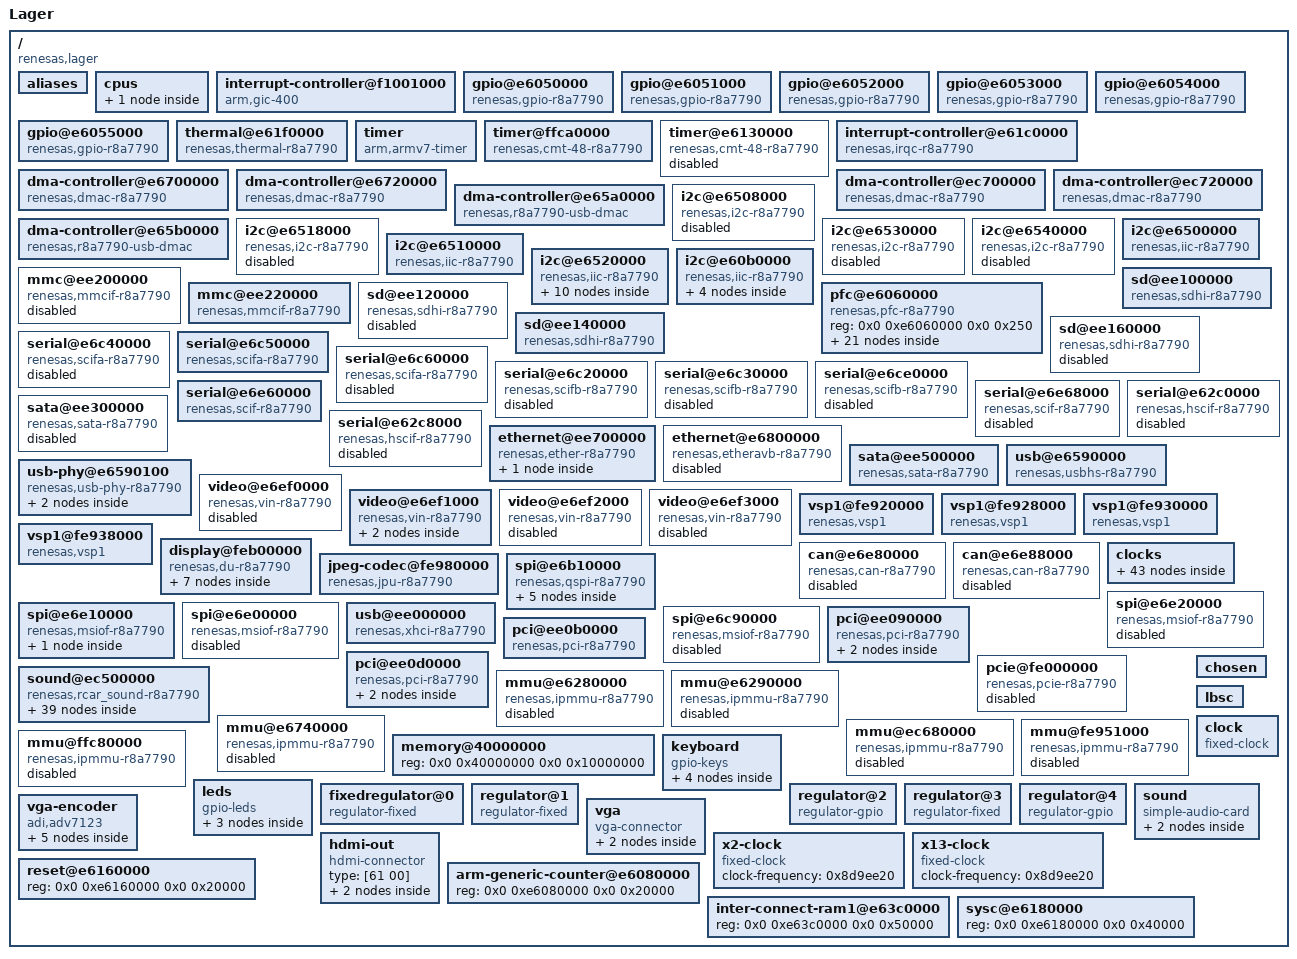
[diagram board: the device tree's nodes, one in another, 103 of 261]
/dts-v1/;

/ {
	compatible = "renesas,lager", "renesas,r8a7790";
	interrupt-parent = <0x1>;
	#address-cells = <0x2>;
	#size-cells = <0x2>;
	model = "Lager";

	aliases {
		i2c0 = "/i2c@e6508000";
		i2c1 = "/i2c@e6518000";
		i2c2 = "/i2c@e6530000";
		i2c3 = "/i2c@e6540000";
		i2c4 = "/i2c@e6500000";
		i2c5 = "/i2c@e6510000";
		i2c6 = "/i2c@e6520000";
		i2c7 = "/i2c@e60b0000";
		spi0 = "/spi@e6b10000";
		spi1 = "/spi@e6e20000";
		spi2 = "/spi@e6e10000";
		spi3 = "/spi@e6e00000";
		spi4 = "/spi@e6c90000";
		vin0 = "/video@e6ef0000";
		vin1 = "/video@e6ef1000";
		vin2 = "/video@e6ef2000";
		vin3 = "/video@e6ef3000";
		serial6 = "/serial@e6e60000";
		serial7 = "/serial@e6e68000";
	};

	cpus {
		#address-cells = <0x1>;
		#size-cells = <0x0>;

		cpu@0 {
			device_type = "cpu";
			compatible = "arm,gic-400";
			reg = <0x0>;
			clock-frequency = "M|m";
			voltage-tolerance = <0x1>;
			clocks = <0x2 0x9>;
			clock-latency = <0x493e0>;
			operating-points = <0x155cc0 0xf4240 0x12b128 0xf4240 0x100590 0xf4240 0xd59f8 0xf4240 0xaae60 0xf4240 0x55730 0xf4240>;
			cpu0-supply = <0x3>;
		};
	};

	interrupt-controller@f1001000 {
		compatible = "arm,gic-400";
		#interrupt-cells = <0x3>;
		#address-cells = <0x0>;
		interrupt-controller;
		reg = <0x0 0xf1001000 0x0 0x1000 0x0 0xf1002000 0x0 0x1000 0x0 0xf1004000 0x0 0x2000 0x0 0xf1006000 0x0 0x2000>;
		interrupts = <0x1 0x9 0xf04>;
		linux,phandle = <0x1>;
		phandle = <0x1>;
	};

	gpio@e6050000 {
		compatible = "renesas,gpio-r8a7790", "renesas,gpio-rcar";
		reg = <0x0 0xe6050000 0x0 0x50>;
		interrupts = <0x0 0x4 0x4>;
		#gpio-cells = <0x2>;
		gpio-controller;
		gpio-ranges = <0x4 0x0 0x0 0x20>;
		#interrupt-cells = <0x2>;
		interrupt-controller;
		clocks = <0x5 0xc>;
		power-domains = <0x2>;
	};

	gpio@e6051000 {
		compatible = "renesas,gpio-r8a7790", "renesas,gpio-rcar";
		reg = <0x0 0xe6051000 0x0 0x50>;
		interrupts = <0x0 0x5 0x4>;
		#gpio-cells = <0x2>;
		gpio-controller;
		gpio-ranges = <0x4 0x0 0x20 0x1e>;
		#interrupt-cells = <0x2>;
		interrupt-controller;
		clocks = <0x5 0xb>;
		power-domains = <0x2>;
		linux,phandle = <0x11>;
		phandle = <0x11>;
	};

	gpio@e6052000 {
		compatible = "renesas,gpio-r8a7790", "renesas,gpio-rcar";
		reg = <0x0 0xe6052000 0x0 0x50>;
		interrupts = <0x0 0x6 0x4>;
		#gpio-cells = <0x2>;
		gpio-controller;
		gpio-ranges = <0x4 0x0 0x40 0x1e>;
		#interrupt-cells = <0x2>;
		interrupt-controller;
		clocks = <0x5 0xa>;
		power-domains = <0x2>;
	};

	gpio@e6053000 {
		compatible = "renesas,gpio-r8a7790", "renesas,gpio-rcar";
		reg = <0x0 0xe6053000 0x0 0x50>;
		interrupts = <0x0 0x7 0x4>;
		#gpio-cells = <0x2>;
		gpio-controller;
		gpio-ranges = <0x4 0x0 0x60 0x20>;
		#interrupt-cells = <0x2>;
		interrupt-controller;
		clocks = <0x5 0x9>;
		power-domains = <0x2>;
		linux,phandle = <0x1c>;
		phandle = <0x1c>;
	};

	gpio@e6054000 {
		compatible = "renesas,gpio-r8a7790", "renesas,gpio-rcar";
		reg = <0x0 0xe6054000 0x0 0x50>;
		interrupts = <0x0 0x8 0x4>;
		#gpio-cells = <0x2>;
		gpio-controller;
		gpio-ranges = <0x4 0x0 0x80 0x20>;
		#interrupt-cells = <0x2>;
		interrupt-controller;
		clocks = <0x5 0x8>;
		power-domains = <0x2>;
		linux,phandle = <0x5a>;
		phandle = <0x5a>;
	};

	gpio@e6055000 {
		compatible = "renesas,gpio-r8a7790", "renesas,gpio-rcar";
		reg = <0x0 0xe6055000 0x0 0x50>;
		interrupts = <0x0 0x9 0x4>;
		#gpio-cells = <0x2>;
		gpio-controller;
		gpio-ranges = <0x4 0x0 0xa0 0x20>;
		#interrupt-cells = <0x2>;
		interrupt-controller;
		clocks = <0x5 0x7>;
		power-domains = <0x2>;
		linux,phandle = <0x2b>;
		phandle = <0x2b>;
	};

	thermal@e61f0000 {
		compatible = "renesas,thermal-r8a7790", "renesas,rcar-thermal";
		reg = <0x0 0xe61f0000 0x0 0x14 0x0 0xe61f0100 0x0 0x38>;
		interrupts = <0x0 0x45 0x4>;
		clocks = <0x6 0x16>;
		power-domains = <0x2>;
	};

	timer {
		compatible = "arm,armv7-timer";
		interrupts = <0x1 0xd 0xf08 0x1 0xe 0xf08 0x1 0xb 0xf08 0x1 0xa 0xf08>;
	};

	timer@ffca0000 {
		compatible = "renesas,cmt-48-r8a7790", "renesas,cmt-48-gen2";
		reg = <0x0 0xffca0000 0x0 0x1004>;
		interrupts = <0x0 0x8e 0x4 0x0 0x8f 0x4>;
		clocks = <0x7 0x18>;
		clock-names = "fck";
		power-domains = <0x2>;
		renesas,channels-mask = <0x60>;
		status = "okay";
	};

	timer@e6130000 {
		compatible = "renesas,cmt-48-r8a7790", "renesas,cmt-48-gen2";
		reg = <0x0 0xe6130000 0x0 0x1004>;
		interrupts = <0x0 0x78 0x4 0x0 0x79 0x4 0x0 0x7a 0x4 0x0 0x7b 0x4 0x0 0x7c 0x4 0x0 0x7d 0x4 0x0 0x7e 0x4 0x0 0x7f 0x4>;
		clocks = <0x8 0x1d>;
		clock-names = "fck";
		power-domains = <0x2>;
		renesas,channels-mask = <0xff>;
		status = "disabled";
	};

	interrupt-controller@e61c0000 {
		compatible = "renesas,irqc-r8a7790", "renesas,irqc";
		#interrupt-cells = <0x2>;
		interrupt-controller;
		reg = <0x0 0xe61c0000 0x0 0x200>;
		interrupts = <0x0 0x0 0x4 0x0 0x1 0x4 0x0 0x2 0x4 0x0 0x3 0x4>;
		clocks = <0x9 0x7>;
		power-domains = <0x2>;
		linux,phandle = <0x15>;
		phandle = <0x15>;
	};

	dma-controller@e6700000 {
		compatible = "renesas,dmac-r8a7790", "renesas,rcar-dmac";
		reg = <0x0 0xe6700000 0x0 0x20000>;
		interrupts = <0x0 0xc5 0x4 0x0 0xc8 0x4 0x0 0xc9 0x4 0x0 0xca 0x4 0x0 0xcb 0x4 0x0 0xcc 0x4 0x0 0xcd 0x4 0x0 0xce 0x4 0x0 0xcf 0x4 0x0 0xd0 0x4 0x0 0xd1 0x4 0x0 0xd2 0x4 0x0 0xd3 0x4 0x0 0xd4 0x4 0x0 0xd5 0x4 0x0 0xd6 0x4>;
		interrupt-names = "error", "ch0", "ch1", "ch2", "ch3", "ch4", "ch5", "ch6", "ch7", "ch8", "ch9", "ch10", "ch11", "ch12", "ch13", "ch14";
		clocks = <0xa 0x13>;
		clock-names = "fck";
		power-domains = <0x2>;
		#dma-cells = <0x1>;
		dma-channels = <0xf>;
		linux,phandle = <0xb>;
		phandle = <0xb>;
	};

	dma-controller@e6720000 {
		compatible = "renesas,dmac-r8a7790", "renesas,rcar-dmac";
		reg = <0x0 0xe6720000 0x0 0x20000>;
		interrupts = <0x0 0xdc 0x4 0x0 0xd8 0x4 0x0 0xd9 0x4 0x0 0xda 0x4 0x0 0xdb 0x4 0x0 0x134 0x4 0x0 0x135 0x4 0x0 0x136 0x4 0x0 0x137 0x4 0x0 0x138 0x4 0x0 0x139 0x4 0x0 0x13a 0x4 0x0 0x13b 0x4 0x0 0x13c 0x4 0x0 0x13d 0x4 0x0 0x13e 0x4>;
		interrupt-names = "error", "ch0", "ch1", "ch2", "ch3", "ch4", "ch5", "ch6", "ch7", "ch8", "ch9", "ch10", "ch11", "ch12", "ch13", "ch14";
		clocks = <0xa 0x12>;
		clock-names = "fck";
		power-domains = <0x2>;
		#dma-cells = <0x1>;
		dma-channels = <0xf>;
		linux,phandle = <0x18>;
		phandle = <0x18>;
	};

	dma-controller@ec700000 {
		compatible = "renesas,dmac-r8a7790", "renesas,rcar-dmac";
		reg = <0x0 0xec700000 0x0 0x10000>;
		interrupts = <0x0 0x15a 0x4 0x0 0x140 0x4 0x0 0x141 0x4 0x0 0x142 0x4 0x0 0x143 0x4 0x0 0x144 0x4 0x0 0x145 0x4 0x0 0x146 0x4 0x0 0x147 0x4 0x0 0x148 0x4 0x0 0x149 0x4 0x0 0x14a 0x4 0x0 0x14b 0x4 0x0 0x14c 0x4>;
		interrupt-names = "error", "ch0", "ch1", "ch2", "ch3", "ch4", "ch5", "ch6", "ch7", "ch8", "ch9", "ch10", "ch11", "ch12";
		clocks = <0x6 0x2>;
		clock-names = "fck";
		power-domains = <0x2>;
		#dma-cells = <0x1>;
		dma-channels = <0xd>;
		linux,phandle = <0x52>;
		phandle = <0x52>;
	};

	dma-controller@ec720000 {
		compatible = "renesas,dmac-r8a7790", "renesas,rcar-dmac";
		reg = <0x0 0xec720000 0x0 0x10000>;
		interrupts = <0x0 0x15b 0x4 0x0 0x14d 0x4 0x0 0x14e 0x4 0x0 0x14f 0x4 0x0 0x150 0x4 0x0 0x151 0x4 0x0 0x152 0x4 0x0 0x153 0x4 0x0 0x154 0x4 0x0 0x155 0x4 0x0 0x156 0x4 0x0 0x157 0x4 0x0 0x158 0x4 0x0 0x159 0x4>;
		interrupt-names = "error", "ch0", "ch1", "ch2", "ch3", "ch4", "ch5", "ch6", "ch7", "ch8", "ch9", "ch10", "ch11", "ch12";
		clocks = <0x6 0x1>;
		clock-names = "fck";
		power-domains = <0x2>;
		#dma-cells = <0x1>;
		dma-channels = <0xd>;
		linux,phandle = <0x53>;
		phandle = <0x53>;
	};

	dma-controller@e65a0000 {
		compatible = "renesas,r8a7790-usb-dmac", "renesas,usb-dmac";
		reg = <0x0 0xe65a0000 0x0 0x100>;
		interrupts = <0x0 0x6d 0x4 0x0 0x6d 0x4>;
		interrupt-names = "ch0", "ch1";
		clocks = <0x8 0x1e>;
		power-domains = <0x2>;
		#dma-cells = <0x1>;
		dma-channels = <0x2>;
		linux,phandle = <0x27>;
		phandle = <0x27>;
	};

	dma-controller@e65b0000 {
		compatible = "renesas,r8a7790-usb-dmac", "renesas,usb-dmac";
		reg = <0x0 0xe65b0000 0x0 0x100>;
		interrupts = <0x0 0x6e 0x4 0x0 0x6e 0x4>;
		interrupt-names = "ch0", "ch1";
		clocks = <0x8 0x1f>;
		power-domains = <0x2>;
		#dma-cells = <0x1>;
		dma-channels = <0x2>;
		linux,phandle = <0x28>;
		phandle = <0x28>;
	};

	i2c@e6508000 {
		#address-cells = <0x1>;
		#size-cells = <0x0>;
		compatible = "renesas,i2c-r8a7790";
		reg = <0x0 0xe6508000 0x0 0x40>;
		interrupts = <0x0 0x11f 0x4>;
		clocks = <0x5 0x1f>;
		power-domains = <0x2>;
		i2c-scl-internal-delay-ns = <0x6e>;
		status = "disabled";
	};

	i2c@e6518000 {
		#address-cells = <0x1>;
		#size-cells = <0x0>;
		compatible = "renesas,i2c-r8a7790";
		reg = <0x0 0xe6518000 0x0 0x40>;
		interrupts = <0x0 0x120 0x4>;
		clocks = <0x5 0x1e>;
		power-domains = <0x2>;
		i2c-scl-internal-delay-ns = <0x6>;
		status = "disabled";
	};

	i2c@e6530000 {
		#address-cells = <0x1>;
		#size-cells = <0x0>;
		compatible = "renesas,i2c-r8a7790";
		reg = <0x0 0xe6530000 0x0 0x40>;
		interrupts = <0x0 0x11e 0x4>;
		clocks = <0x5 0x1d>;
		power-domains = <0x2>;
		i2c-scl-internal-delay-ns = <0x6>;
		status = "disabled";
	};

	i2c@e6540000 {
		#address-cells = <0x1>;
		#size-cells = <0x0>;
		compatible = "renesas,i2c-r8a7790";
		reg = <0x0 0xe6540000 0x0 0x40>;
		interrupts = <0x0 0x122 0x4>;
		clocks = <0x5 0x1c>;
		power-domains = <0x2>;
		i2c-scl-internal-delay-ns = <0x6e>;
		status = "disabled";
	};

	i2c@e6500000 {
		#address-cells = <0x1>;
		#size-cells = <0x0>;
		compatible = "renesas,iic-r8a7790", "renesas,rmobile-iic";
		reg = <0x0 0xe6500000 0x0 0x425>;
		interrupts = <0x0 0xae 0x4>;
		clocks = <0x8 0x12>;
		dmas = <0xb 0x61 0xb 0x62>;
		dma-names = "tx", "rx";
		power-domains = <0x2>;
		status = "okay";
		pinctrl-0 = <0xc>;
		pinctrl-names = "default";
	};

	i2c@e6510000 {
		#address-cells = <0x1>;
		#size-cells = <0x0>;
		compatible = "renesas,iic-r8a7790", "renesas,rmobile-iic";
		reg = <0x0 0xe6510000 0x0 0x425>;
		interrupts = <0x0 0xaf 0x4>;
		clocks = <0x8 0x17>;
		dmas = <0xb 0x65 0xb 0x66>;
		dma-names = "tx", "rx";
		power-domains = <0x2>;
		status = "okay";
		pinctrl-0 = <0xd>;
		pinctrl-names = "default";
	};

	i2c@e6520000 {
		#address-cells = <0x1>;
		#size-cells = <0x0>;
		compatible = "renesas,iic-r8a7790", "renesas,rmobile-iic";
		reg = <0x0 0xe6520000 0x0 0x425>;
		interrupts = <0x0 0xb0 0x4>;
		clocks = <0x8 0x0>;
		dmas = <0xb 0x69 0xb 0x6a>;
		dma-names = "tx", "rx";
		power-domains = <0x2>;
		status = "okay";
		pinctrl-0 = <0xe>;
		pinctrl-names = "default";
		clock-frequency = <0x186a0>;

		codec@12 {
			compatible = "asahi-kasei,ak4643";
			#sound-dai-cells = <0x0>;
			reg = <0x12>;
			linux,phandle = <0x5d>;
			phandle = <0x5d>;
		};

		composite-in@20 {
			compatible = "adi,adv7180";
			reg = <0x20>;
			remote = <0xf>;

			port {

				endpoint {
					bus-width = <0x8>;
					remote-endpoint = <0x10>;
					linux,phandle = <0x2d>;
					phandle = <0x2d>;
				};
			};
		};

		hdmi@39 {
			compatible = "adi,adv7511w";
			reg = <0x39>;
			interrupt-parent = <0x11>;
			interrupts = <0xf 0x8>;
			adi,input-depth = <0x8>;
			adi,input-colorspace = "rgb";
			adi,input-clock = "1x";
			adi,input-style = <0x1>;
			adi,input-justification = "evenly";

			ports {
				#address-cells = <0x1>;
				#size-cells = <0x0>;

				port@0 {
					reg = <0x0>;

					endpoint {
						remote-endpoint = <0x12>;
						linux,phandle = <0x32>;
						phandle = <0x32>;
					};
				};

				port@1 {
					reg = <0x1>;

					endpoint {
						remote-endpoint = <0x13>;
						linux,phandle = <0x62>;
						phandle = <0x62>;
					};
				};
			};
		};
	};

	i2c@e60b0000 {
		#address-cells = <0x1>;
		#size-cells = <0x0>;
		compatible = "renesas,iic-r8a7790", "renesas,rmobile-iic";
		reg = <0x0 0xe60b0000 0x0 0x425>;
		interrupts = <0x0 0xad 0x4>;
		clocks = <0x5 0x1a>;
		dmas = <0xb 0x77 0xb 0x78>;
		dma-names = "tx", "rx";
		power-domains = <0x2>;
		status = "okay";
		pinctrl-names = "default";
		pinctrl-0 = <0x14>;

		pmic@58 {
			compatible = "dlg,da9063";
			reg = <0x58>;
			interrupt-parent = <0x15>;
			interrupts = <0x2 0x8>;
			interrupt-controller;

			rtc {
				compatible = "dlg,da9063-rtc";
			};

			wdt {
				compatible = "dlg,da9063-watchdog";
			};
		};

		regulator@68 {
			compatible = "dlg,da9210";
			reg = <0x68>;
			interrupt-parent = <0x15>;
			interrupts = <0x2 0x8>;
			regulator-min-microvolt = <0xf4240>;
			regulator-max-microvolt = <0xf4240>;
			regulator-boot-on;
			regulator-always-on;
			linux,phandle = <0x3>;
			phandle = <0x3>;
		};
	};

	mmc@ee200000 {
		compatible = "renesas,mmcif-r8a7790", "renesas,sh-mmcif";
		reg = <0x0 0xee200000 0x0 0x80>;
		interrupts = <0x0 0xa9 0x4>;
		clocks = <0x8 0xf>;
		dmas = <0xb 0xd1 0xb 0xd2>;
		dma-names = "tx", "rx";
		power-domains = <0x2>;
		reg-io-width = <0x4>;
		status = "disabled";
		max-frequency = <0x5cfbb60>;
	};

	mmc@ee220000 {
		compatible = "renesas,mmcif-r8a7790", "renesas,sh-mmcif";
		reg = <0x0 0xee220000 0x0 0x80>;
		interrupts = <0x0 0xaa 0x4>;
		clocks = <0x8 0x5>;
		dmas = <0xb 0xe1 0xb 0xe2>;
		dma-names = "tx", "rx";
		power-domains = <0x2>;
		reg-io-width = <0x4>;
		status = "okay";
		max-frequency = <0x5cfbb60>;
		pinctrl-0 = <0x16>;
		pinctrl-names = "default";
		vmmc-supply = <0x17>;
		bus-width = <0x8>;
		non-removable;
	};

	pfc@e6060000 {
		compatible = "renesas,pfc-r8a7790";
		reg = <0x0 0xe6060000 0x0 0x250>;
		linux,phandle = <0x4>;
		phandle = <0x4>;

		du {
			renesas,groups = "du_rgb666", "du_sync_1", "du_clk_out_0";
			renesas,function = "du";
			linux,phandle = <0x30>;
			phandle = <0x30>;
		};

		serial0 {
			renesas,groups = "scif0_data";
			renesas,function = "scif0";
			linux,phandle = <0x22>;
			phandle = <0x22>;
		};

		ether {
			renesas,groups = "eth_link", "eth_mdio", "eth_rmii";
			renesas,function = "eth";
			linux,phandle = <0x24>;
			phandle = <0x24>;
		};

		phy1 {
			renesas,groups = "intc_irq0";
			renesas,function = "intc";
			linux,phandle = <0x25>;
			phandle = <0x25>;
		};

		serial1 {
			renesas,groups = "scifa1_data";
			renesas,function = "scifa1";
			linux,phandle = <0x20>;
			phandle = <0x20>;
		};

		sd0 {
			renesas,groups = "sdhi0_data4", "sdhi0_ctrl";
			renesas,function = "sdhi0";
			linux,phandle = <0x19>;
			phandle = <0x19>;
		};

		sd2 {
			renesas,groups = "sdhi2_data4", "sdhi2_ctrl";
			renesas,function = "sdhi2";
			linux,phandle = <0x1d>;
			phandle = <0x1d>;
		};

		mmc1 {
			renesas,groups = "mmc1_data8", "mmc1_ctrl";
			renesas,function = "mmc1";
			linux,phandle = <0x16>;
			phandle = <0x16>;
		};

		spi0 {
			renesas,groups = "qspi_ctrl", "qspi_data4";
			renesas,function = "qspi";
			linux,phandle = <0x45>;
			phandle = <0x45>;
		};

		spi2 {
			renesas,groups = "msiof1_clk", "msiof1_sync", "msiof1_rx", "msiof1_tx";
			renesas,function = "msiof1";
			linux,phandle = <0x47>;
			phandle = <0x47>;
		};

		iic0 {
			renesas,groups = "iic0";
			renesas,function = "iic0";
			linux,phandle = <0xc>;
			phandle = <0xc>;
		};

		iic1 {
			renesas,groups = "iic1";
			renesas,function = "iic1";
			linux,phandle = <0xd>;
			phandle = <0xd>;
		};

		iic2 {
			renesas,groups = "iic2";
			renesas,function = "iic2";
			linux,phandle = <0xe>;
			phandle = <0xe>;
		};

		iic3 {
			renesas,groups = "iic3";
			renesas,function = "iic3";
			linux,phandle = <0x14>;
			phandle = <0x14>;
		};

		hsusb {
			renesas,groups = "usb0_ovc_vbus";
			renesas,function = "usb0";
			linux,phandle = <0x2a>;
			phandle = <0x2a>;
		};

		usb0 {
			renesas,groups = "usb0";
			renesas,function = "usb0";
			linux,phandle = <0x4a>;
			phandle = <0x4a>;
		};

		usb1 {
			renesas,groups = "usb1";
			renesas,function = "usb1";
			linux,phandle = <0x4b>;
			phandle = <0x4b>;
		};

		usb2 {
			renesas,groups = "usb2";
			renesas,function = "usb2";
			linux,phandle = <0x49>;
			phandle = <0x49>;
		};

		vin {
			renesas,groups = "vin1_data8", "vin1_clk";
			renesas,function = "vin1";
			linux,phandle = <0x2c>;
			phandle = <0x2c>;
		};

		sound {
			renesas,groups = "ssi0129_ctrl", "ssi0_data", "ssi1_data";
			renesas,function = "ssi";
			linux,phandle = <0x50>;
			phandle = <0x50>;
		};

		sound_clk {
			renesas,groups = "audio_clk_a";
			renesas,function = "audio_clk";
			linux,phandle = <0x51>;
			phandle = <0x51>;
		};
	};

	sd@ee100000 {
		compatible = "renesas,sdhi-r8a7790";
		reg = <0x0 0xee100000 0x0 0x328>;
		interrupts = <0x0 0xa5 0x4>;
		clocks = <0x8 0xe>;
		dmas = <0x18 0xcd 0x18 0xce>;
		dma-names = "tx", "rx";
		power-domains = <0x2>;
		status = "okay";
		pinctrl-0 = <0x19>;
		pinctrl-names = "default";
		vmmc-supply = <0x1a>;
		vqmmc-supply = <0x1b>;
		cd-gpios = <0x1c 0x6 0x1>;
	};

	sd@ee120000 {
		compatible = "renesas,sdhi-r8a7790";
		reg = <0x0 0xee120000 0x0 0x328>;
		interrupts = <0x0 0xa6 0x4>;
		clocks = <0x8 0xd>;
		dmas = <0x18 0xc9 0x18 0xca>;
		dma-names = "tx", "rx";
		power-domains = <0x2>;
		status = "disabled";
	};

	sd@ee140000 {
		compatible = "renesas,sdhi-r8a7790";
		reg = <0x0 0xee140000 0x0 0x100>;
		interrupts = <0x0 0xa7 0x4>;
		clocks = <0x8 0xc>;
		dmas = <0x18 0xc1 0x18 0xc2>;
		dma-names = "tx", "rx";
		power-domains = <0x2>;
		status = "okay";
		pinctrl-0 = <0x1d>;
		pinctrl-names = "default";
		vmmc-supply = <0x1e>;
		vqmmc-supply = <0x1f>;
		cd-gpios = <0x1c 0x16 0x1>;
	};

	sd@ee160000 {
		compatible = "renesas,sdhi-r8a7790";
		reg = <0x0 0xee160000 0x0 0x100>;
		interrupts = <0x0 0xa8 0x4>;
		clocks = <0x8 0xb>;
		dmas = <0x18 0xd3 0x18 0xd4>;
		dma-names = "tx", "rx";
		power-domains = <0x2>;
		status = "disabled";
	};

	serial@e6c40000 {
		compatible = "renesas,scifa-r8a7790", "renesas,scifa";
		reg = <0x0 0xe6c40000 0x0 0x40>;
		interrupts = <0x0 0x90 0x4>;
		clocks = <0xa 0x4>;
		clock-names = "sci_ick";
		dmas = <0xb 0x21 0xb 0x22>;
		dma-names = "tx", "rx";
		power-domains = <0x2>;
		status = "disabled";
	};

	serial@e6c50000 {
		compatible = "renesas,scifa-r8a7790", "renesas,scifa";
		reg = <0x0 0xe6c50000 0x0 0x40>;
		interrupts = <0x0 0x91 0x4>;
		clocks = <0xa 0x3>;
		clock-names = "sci_ick";
		dmas = <0xb 0x25 0xb 0x26>;
		dma-names = "tx", "rx";
		power-domains = <0x2>;
		status = "okay";
		pinctrl-0 = <0x20>;
		pinctrl-names = "default";
	};

	serial@e6c60000 {
		compatible = "renesas,scifa-r8a7790", "renesas,scifa";
		reg = <0x0 0xe6c60000 0x0 0x40>;
		interrupts = <0x0 0x97 0x4>;
		clocks = <0xa 0x2>;
		clock-names = "sci_ick";
		dmas = <0xb 0x27 0xb 0x28>;
		dma-names = "tx", "rx";
		power-domains = <0x2>;
		status = "disabled";
	};

	serial@e6c20000 {
		compatible = "renesas,scifb-r8a7790", "renesas,scifb";
		reg = <0x0 0xe6c20000 0x0 0x40>;
		interrupts = <0x0 0x94 0x4>;
		clocks = <0xa 0x6>;
		clock-names = "sci_ick";
		dmas = <0xb 0x3d 0xb 0x3e>;
		dma-names = "tx", "rx";
		power-domains = <0x2>;
		status = "disabled";
	};

	serial@e6c30000 {
		compatible = "renesas,scifb-r8a7790", "renesas,scifb";
		reg = <0x0 0xe6c30000 0x0 0x40>;
		interrupts = <0x0 0x95 0x4>;
		clocks = <0xa 0x7>;
		clock-names = "sci_ick";
		dmas = <0xb 0x19 0xb 0x1a>;
		dma-names = "tx", "rx";
		power-domains = <0x2>;
		status = "disabled";
	};

	serial@e6ce0000 {
		compatible = "renesas,scifb-r8a7790", "renesas,scifb";
		reg = <0x0 0xe6ce0000 0x0 0x40>;
		interrupts = <0x0 0x96 0x4>;
		clocks = <0xa 0x10>;
		clock-names = "sci_ick";
		dmas = <0xb 0x1d 0xb 0x1e>;
		dma-names = "tx", "rx";
		power-domains = <0x2>;
		status = "disabled";
	};

	serial@e6e60000 {
		compatible = "renesas,scif-r8a7790", "renesas,scif";
		reg = <0x0 0xe6e60000 0x0 0x40>;
		interrupts = <0x0 0x98 0x4>;
		clocks = <0x21 0x15>;
		clock-names = "sci_ick";
		dmas = <0xb 0x29 0xb 0x2a>;
		dma-names = "tx", "rx";
		power-domains = <0x2>;
		status = "ok";
		pinctrl-0 = <0x22>;
		pinctrl-names = "default";
	};

	serial@e6e68000 {
		compatible = "renesas,scif-r8a7790", "renesas,scif";
		reg = <0x0 0xe6e68000 0x0 0x40>;
		interrupts = <0x0 0x99 0x4>;
		clocks = <0x21 0x14>;
		clock-names = "sci_ick";
		dmas = <0xb 0x2d 0xb 0x2e>;
		dma-names = "tx", "rx";
		power-domains = <0x2>;
		status = "disabled";
	};

	serial@e62c0000 {
		compatible = "renesas,hscif-r8a7790", "renesas,hscif";
		reg = <0x0 0xe62c0000 0x0 0x60>;
		interrupts = <0x0 0x9a 0x4>;
		clocks = <0x21 0x11>;
		clock-names = "sci_ick";
		dmas = <0xb 0x39 0xb 0x3a>;
		dma-names = "tx", "rx";
		power-domains = <0x2>;
		status = "disabled";
	};

	serial@e62c8000 {
		compatible = "renesas,hscif-r8a7790", "renesas,hscif";
		reg = <0x0 0xe62c8000 0x0 0x60>;
		interrupts = <0x0 0x9b 0x4>;
		clocks = <0x21 0x10>;
		clock-names = "sci_ick";
		dmas = <0xb 0x4d 0xb 0x4e>;
		dma-names = "tx", "rx";
		power-domains = <0x2>;
		status = "disabled";
	};

	ethernet@ee700000 {
		compatible = "renesas,ether-r8a7790";
		reg = <0x0 0xee700000 0x0 0x400>;
		interrupts = <0x0 0xa2 0x4>;
		clocks = <0x23 0xd>;
		phy-mode = "rmii";
		power-domains = <0x2>;
		#address-cells = <0x1>;
		#size-cells = <0x0>;
		status = "okay";
		pinctrl-0 = <0x24 0x25>;
		pinctrl-names = "default";
		phy-handle = <0x26>;
		renesas,ether-link-active-low;

		ethernet-phy@1 {
			reg = <0x1>;
			interrupt-parent = <0x15>;
			interrupts = <0x0 0x8>;
			micrel,led-mode = <0x1>;
			linux,phandle = <0x26>;
			phandle = <0x26>;
		};
	};

	ethernet@e6800000 {
		compatible = "renesas,etheravb-r8a7790";
		reg = <0x0 0xe6800000 0x0 0x7bf>;
		interrupts = <0x0 0xa3 0x4>;
		clocks = <0x23 0xc>;
		power-domains = <0x2>;
		#address-cells = <0x1>;
		#size-cells = <0x0>;
		status = "disabled";
	};

	sata@ee300000 {
		compatible = "renesas,sata-r8a7790";
		reg = <0x0 0xee300000 0x0 0x2000>;
		interrupts = <0x0 0x69 0x4>;
		clocks = <0x23 0xf>;
		power-domains = <0x2>;
		status = "disabled";
	};

	sata@ee500000 {
		compatible = "renesas,sata-r8a7790";
		reg = <0x0 0xee500000 0x0 0x2000>;
		interrupts = <0x0 0x6a 0x4>;
		clocks = <0x23 0xe>;
		power-domains = <0x2>;
		status = "okay";
	};

	usb@e6590000 {
		compatible = "renesas,usbhs-r8a7790";
		reg = <0x0 0xe6590000 0x0 0x100>;
		interrupts = <0x0 0x6b 0x4>;
		clocks = <0x21 0x4>;
		dmas = <0x27 0x0 0x27 0x1 0x28 0x0 0x28 0x1>;
		dma-names = "ch0", "ch1", "ch2", "ch3";
		power-domains = <0x2>;
		renesas,buswait = <0x4>;
		phys = <0x29 0x1>;
		phy-names = "usb";
		status = "okay";
		pinctrl-0 = <0x2a>;
		pinctrl-names = "default";
		renesas,enable-gpio = <0x2b 0x12 0x0>;
	};

	usb-phy@e6590100 {
		compatible = "renesas,usb-phy-r8a7790";
		reg = <0x0 0xe6590100 0x0 0x100>;
		#address-cells = <0x1>;
		#size-cells = <0x0>;
		clocks = <0x21 0x4>;
		clock-names = "usbhs";
		power-domains = <0x2>;
		status = "okay";

		usb-channel@0 {
			reg = <0x0>;
			#phy-cells = <0x1>;
			linux,phandle = <0x29>;
			phandle = <0x29>;
		};

		usb-channel@2 {
			reg = <0x2>;
			#phy-cells = <0x1>;
			linux,phandle = <0x48>;
			phandle = <0x48>;
		};
	};

	video@e6ef0000 {
		compatible = "renesas,vin-r8a7790";
		reg = <0x0 0xe6ef0000 0x0 0x1000>;
		interrupts = <0x0 0xbc 0x4>;
		clocks = <0x23 0xb>;
		power-domains = <0x2>;
		status = "disabled";
	};

	video@e6ef1000 {
		compatible = "renesas,vin-r8a7790";
		reg = <0x0 0xe6ef1000 0x0 0x1000>;
		interrupts = <0x0 0xbd 0x4>;
		clocks = <0x23 0xa>;
		power-domains = <0x2>;
		status = "okay";
		pinctrl-0 = <0x2c>;
		pinctrl-names = "default";
		linux,phandle = <0xf>;
		phandle = <0xf>;

		port {
			#address-cells = <0x1>;
			#size-cells = <0x0>;

			endpoint {
				remote-endpoint = <0x2d>;
				bus-width = <0x8>;
				linux,phandle = <0x10>;
				phandle = <0x10>;
			};
		};
	};

	video@e6ef2000 {
		compatible = "renesas,vin-r8a7790";
		reg = <0x0 0xe6ef2000 0x0 0x1000>;
		interrupts = <0x0 0xbe 0x4>;
		clocks = <0x23 0x9>;
		power-domains = <0x2>;
		status = "disabled";
	};

	video@e6ef3000 {
		compatible = "renesas,vin-r8a7790";
		reg = <0x0 0xe6ef3000 0x0 0x1000>;
		interrupts = <0x0 0xbf 0x4>;
		clocks = <0x23 0x8>;
		power-domains = <0x2>;
		status = "disabled";
	};

	vsp1@fe920000 {
		compatible = "renesas,vsp1";
		reg = <0x0 0xfe920000 0x0 0x8000>;
		interrupts = <0x0 0x10a 0x4>;
		clocks = <0x7 0x1e>;
		power-domains = <0x2>;
		renesas,has-sru;
		renesas,#rpf = <0x5>;
		renesas,#uds = <0x1>;
		renesas,#wpf = <0x4>;
	};

	vsp1@fe928000 {
		compatible = "renesas,vsp1";
		reg = <0x0 0xfe928000 0x0 0x8000>;
		interrupts = <0x0 0x10b 0x4>;
		clocks = <0x7 0x1f>;
		power-domains = <0x2>;
		renesas,has-lut;
		renesas,has-sru;
		renesas,#rpf = <0x5>;
		renesas,#uds = <0x3>;
		renesas,#wpf = <0x4>;
	};

	vsp1@fe930000 {
		compatible = "renesas,vsp1";
		reg = <0x0 0xfe930000 0x0 0x8000>;
		interrupts = <0x0 0xf6 0x4>;
		clocks = <0x7 0x1c>;
		power-domains = <0x2>;
		renesas,has-lif;
		renesas,has-lut;
		renesas,#rpf = <0x4>;
		renesas,#uds = <0x1>;
		renesas,#wpf = <0x4>;
	};

	vsp1@fe938000 {
		compatible = "renesas,vsp1";
		reg = <0x0 0xfe938000 0x0 0x8000>;
		interrupts = <0x0 0xf7 0x4>;
		clocks = <0x7 0x1b>;
		power-domains = <0x2>;
		renesas,has-lif;
		renesas,has-lut;
		renesas,#rpf = <0x4>;
		renesas,#uds = <0x1>;
		renesas,#wpf = <0x4>;
	};

	display@feb00000 {
		compatible = "renesas,du-r8a7790";
		reg = <0x0 0xfeb00000 0x0 0x70000 0x0 0xfeb90000 0x0 0x1c 0x0 0xfeb94000 0x0 0x1c>;
		reg-names = "du", "lvds.0", "lvds.1";
		interrupts = <0x0 0x100 0x4 0x0 0x10c 0x4 0x0 0x10d 0x4>;
		clocks = <0x21 0x18 0x21 0x17 0x21 0x16 0x21 0x1a 0x21 0x19 0x2e 0x2f>;
		clock-names = "du.0", "du.1", "du.2", "lvds.0", "lvds.1", "dclkin.0", "dclkin.1";
		status = "okay";
		pinctrl-0 = <0x30>;
		pinctrl-names = "default";

		ports {
			#address-cells = <0x1>;
			#size-cells = <0x0>;

			port@0 {
				reg = <0x0>;

				endpoint {
					remote-endpoint = <0x31>;
					linux,phandle = <0x5f>;
					phandle = <0x5f>;
				};
			};

			port@1 {
				reg = <0x1>;

				endpoint {
					remote-endpoint = <0x32>;
					linux,phandle = <0x12>;
					phandle = <0x12>;
				};
			};

			port@2 {
				reg = <0x2>;

				endpoint {
				};
			};
		};
	};

	can@e6e80000 {
		compatible = "renesas,can-r8a7790";
		reg = <0x0 0xe6e80000 0x0 0x1000>;
		interrupts = <0x0 0xba 0x4>;
		clocks = <0x5 0x10 0x2 0xa 0x33>;
		clock-names = "clkp1", "clkp2", "can_clk";
		power-domains = <0x2>;
		status = "disabled";
	};

	can@e6e88000 {
		compatible = "renesas,can-r8a7790";
		reg = <0x0 0xe6e88000 0x0 0x1000>;
		interrupts = <0x0 0xbb 0x4>;
		clocks = <0x5 0xf 0x2 0xa 0x33>;
		clock-names = "clkp1", "clkp2", "can_clk";
		power-domains = <0x2>;
		status = "disabled";
	};

	jpeg-codec@fe980000 {
		compatible = "renesas,jpu-r8a7790";
		reg = <0x0 0xfe980000 0x0 0x10300>;
		interrupts = <0x0 0x110 0x4>;
		clocks = <0x7 0x6>;
		power-domains = <0x2>;
	};

	clocks {
		#address-cells = <0x2>;
		#size-cells = <0x2>;
		ranges;

		extal_clk {
			compatible = "fixed-clock";
			#clock-cells = <0x0>;
			clock-frequency = <0x1312d00>;
			clock-output-names = "extal";
			linux,phandle = <0x34>;
			phandle = <0x34>;
		};

		pcie_bus_clk {
			compatible = "fixed-clock";
			#clock-cells = <0x0>;
			clock-frequency = <0x5f5e100>;
			clock-output-names = "pcie_bus";
			status = "disabled";
			linux,phandle = <0x4c>;
			phandle = <0x4c>;
		};

		audio_clk_a {
			compatible = "fixed-clock";
			#clock-cells = <0x0>;
			clock-frequency = <0x0>;
			clock-output-names = "audio_clk_a";
			linux,phandle = <0x4d>;
			phandle = <0x4d>;
		};

		audio_clk_b {
			compatible = "fixed-clock";
			#clock-cells = <0x0>;
			clock-frequency = <0x0>;
			clock-output-names = "audio_clk_b";
			linux,phandle = <0x4e>;
			phandle = <0x4e>;
		};

		audio_clk_c {
			compatible = "fixed-clock";
			#clock-cells = <0x0>;
			clock-frequency = <0x0>;
			clock-output-names = "audio_clk_c";
			linux,phandle = <0x4f>;
			phandle = <0x4f>;
		};

		usb_extal_clk {
			compatible = "fixed-clock";
			#clock-cells = <0x0>;
			clock-frequency = <0x2dc6c00>;
			clock-output-names = "usb_extal";
			linux,phandle = <0x35>;
			phandle = <0x35>;
		};

		can_clk {
			compatible = "fixed-clock";
			#clock-cells = <0x0>;
			clock-frequency = <0x0>;
			clock-output-names = "can_clk";
			status = "disabled";
			linux,phandle = <0x33>;
			phandle = <0x33>;
		};

		cpg_clocks@e6150000 {
			compatible = "renesas,r8a7790-cpg-clocks", "renesas,rcar-gen2-cpg-clocks";
			reg = <0x0 0xe6150000 0x0 0x1000>;
			clocks = <0x34 0x35>;
			#clock-cells = <0x1>;
			clock-output-names = "main", "pll0", "pll1", "pll3", "lb", "qspi", "sdh", "sd0", "sd1", "z", "rcan", "adsp";
			#power-domain-cells = <0x0>;
			linux,phandle = <0x2>;
			phandle = <0x2>;
		};

		sd2_clk@e6150078 {
			compatible = "renesas,r8a7790-div6-clock", "renesas,cpg-div6-clock";
			reg = <0x0 0xe6150078 0x0 0x4>;
			clocks = <0x36>;
			#clock-cells = <0x0>;
			clock-output-names = "sd2";
			linux,phandle = <0x41>;
			phandle = <0x41>;
		};

		sd3_clk@e615026c {
			compatible = "renesas,r8a7790-div6-clock", "renesas,cpg-div6-clock";
			reg = <0x0 0xe615026c 0x0 0x4>;
			clocks = <0x36>;
			#clock-cells = <0x0>;
			clock-output-names = "sd3";
			linux,phandle = <0x40>;
			phandle = <0x40>;
		};

		mmc0_clk@e6150240 {
			compatible = "renesas,r8a7790-div6-clock", "renesas,cpg-div6-clock";
			reg = <0x0 0xe6150240 0x0 0x4>;
			clocks = <0x36>;
			#clock-cells = <0x0>;
			clock-output-names = "mmc0";
			linux,phandle = <0x42>;
			phandle = <0x42>;
		};

		mmc1_clk@e6150244 {
			compatible = "renesas,r8a7790-div6-clock", "renesas,cpg-div6-clock";
			reg = <0x0 0xe6150244 0x0 0x4>;
			clocks = <0x36>;
			#clock-cells = <0x0>;
			clock-output-names = "mmc1";
			linux,phandle = <0x3f>;
			phandle = <0x3f>;
		};

		ssp_clk@e6150248 {
			compatible = "renesas,r8a7790-div6-clock", "renesas,cpg-div6-clock";
			reg = <0x0 0xe6150248 0x0 0x4>;
			clocks = <0x36>;
			#clock-cells = <0x0>;
			clock-output-names = "ssp";
		};

		ssprs_clk@e615024c {
			compatible = "renesas,r8a7790-div6-clock", "renesas,cpg-div6-clock";
			reg = <0x0 0xe615024c 0x0 0x4>;
			clocks = <0x36>;
			#clock-cells = <0x0>;
			clock-output-names = "ssprs";
		};

		pll1_div2_clk {
			compatible = "fixed-factor-clock";
			clocks = <0x2 0x2>;
			#clock-cells = <0x0>;
			clock-div = <0x2>;
			clock-mult = <0x1>;
			clock-output-names = "pll1_div2";
			linux,phandle = <0x36>;
			phandle = <0x36>;
		};

		z2_clk {
			compatible = "fixed-factor-clock";
			clocks = <0x2 0x2>;
			#clock-cells = <0x0>;
			clock-div = <0x2>;
			clock-mult = <0x1>;
			clock-output-names = "z2";
		};

		zg_clk {
			compatible = "fixed-factor-clock";
			clocks = <0x2 0x2>;
			#clock-cells = <0x0>;
			clock-div = <0x3>;
			clock-mult = <0x1>;
			clock-output-names = "zg";
			linux,phandle = <0x3b>;
			phandle = <0x3b>;
		};

		zx_clk {
			compatible = "fixed-factor-clock";
			clocks = <0x2 0x2>;
			#clock-cells = <0x0>;
			clock-div = <0x3>;
			clock-mult = <0x1>;
			clock-output-names = "zx";
			linux,phandle = <0x43>;
			phandle = <0x43>;
		};

		zs_clk {
			compatible = "fixed-factor-clock";
			clocks = <0x2 0x2>;
			#clock-cells = <0x0>;
			clock-div = <0x6>;
			clock-mult = <0x1>;
			clock-output-names = "zs";
			linux,phandle = <0x38>;
			phandle = <0x38>;
		};

		hp_clk {
			compatible = "fixed-factor-clock";
			clocks = <0x2 0x2>;
			#clock-cells = <0x0>;
			clock-div = <0xc>;
			clock-mult = <0x1>;
			clock-output-names = "hp";
			linux,phandle = <0x3e>;
			phandle = <0x3e>;
		};

		i_clk {
			compatible = "fixed-factor-clock";
			clocks = <0x2 0x2>;
			#clock-cells = <0x0>;
			clock-div = <0x2>;
			clock-mult = <0x1>;
			clock-output-names = [69 00];
		};

		b_clk {
			compatible = "fixed-factor-clock";
			clocks = <0x2 0x2>;
			#clock-cells = <0x0>;
			clock-div = <0xc>;
			clock-mult = <0x1>;
			clock-output-names = [62 00];
		};

		p_clk {
			compatible = "fixed-factor-clock";
			clocks = <0x2 0x2>;
			#clock-cells = <0x0>;
			clock-div = <0x18>;
			clock-mult = <0x1>;
			clock-output-names = [70 00];
			linux,phandle = <0x3a>;
			phandle = <0x3a>;
		};

		cl_clk {
			compatible = "fixed-factor-clock";
			clocks = <0x2 0x2>;
			#clock-cells = <0x0>;
			clock-div = <0x30>;
			clock-mult = <0x1>;
			clock-output-names = "cl";
		};

		m2_clk {
			compatible = "fixed-factor-clock";
			clocks = <0x2 0x2>;
			#clock-cells = <0x0>;
			clock-div = <0x8>;
			clock-mult = <0x1>;
			clock-output-names = "m2";
			linux,phandle = <0x39>;
			phandle = <0x39>;
		};

		imp_clk {
			compatible = "fixed-factor-clock";
			clocks = <0x2 0x2>;
			#clock-cells = <0x0>;
			clock-div = <0x4>;
			clock-mult = <0x1>;
			clock-output-names = "imp";
		};

		rclk_clk {
			compatible = "fixed-factor-clock";
			clocks = <0x2 0x2>;
			#clock-cells = <0x0>;
			clock-div = <0xc000>;
			clock-mult = <0x1>;
			clock-output-names = "rclk";
			linux,phandle = <0x3c>;
			phandle = <0x3c>;
		};

		oscclk_clk {
			compatible = "fixed-factor-clock";
			clocks = <0x2 0x2>;
			#clock-cells = <0x0>;
			clock-div = <0x3000>;
			clock-mult = <0x1>;
			clock-output-names = "oscclk";
		};

		zb3_clk {
			compatible = "fixed-factor-clock";
			clocks = <0x2 0x3>;
			#clock-cells = <0x0>;
			clock-div = <0x4>;
			clock-mult = <0x1>;
			clock-output-names = "zb3";
		};

		zb3d2_clk {
			compatible = "fixed-factor-clock";
			clocks = <0x2 0x3>;
			#clock-cells = <0x0>;
			clock-div = <0x8>;
			clock-mult = <0x1>;
			clock-output-names = "zb3d2";
		};

		ddr_clk {
			compatible = "fixed-factor-clock";
			clocks = <0x2 0x3>;
			#clock-cells = <0x0>;
			clock-div = <0x8>;
			clock-mult = <0x1>;
			clock-output-names = "ddr";
		};

		mp_clk {
			compatible = "fixed-factor-clock";
			clocks = <0x36>;
			#clock-cells = <0x0>;
			clock-div = <0xf>;
			clock-mult = <0x1>;
			clock-output-names = "mp";
			linux,phandle = <0x37>;
			phandle = <0x37>;
		};

		cp_clk {
			compatible = "fixed-factor-clock";
			clocks = <0x34>;
			#clock-cells = <0x0>;
			clock-div = <0x2>;
			clock-mult = <0x1>;
			clock-output-names = "cp";
			linux,phandle = <0x3d>;
			phandle = <0x3d>;
		};

		mstp0_clks@e6150130 {
			compatible = "renesas,r8a7790-mstp-clocks", "renesas,cpg-mstp-clocks";
			reg = <0x0 0xe6150130 0x0 0x4 0x0 0xe6150030 0x0 0x4>;
			clocks = <0x37>;
			#clock-cells = <0x1>;
			clock-indices = <0x0>;
			clock-output-names = "msiof0";
			linux,phandle = <0x46>;
			phandle = <0x46>;
		};

		mstp1_clks@e6150134 {
			compatible = "renesas,r8a7790-mstp-clocks", "renesas,cpg-mstp-clocks";
			reg = <0x0 0xe6150134 0x0 0x4 0x0 0xe6150038 0x0 0x4>;
			clocks = <0x38 0x38 0x38 0x38 0x39 0x38 0x3a 0x3b 0x38 0x38 0x38 0x38 0x3a 0x3a 0x3c 0x3d 0x38 0x38 0x38 0x38>;
			#clock-cells = <0x1>;
			clock-indices = <0x0 0x1 0x2 0x3 0x6 0x9 0xb 0xc 0xf 0x11 0x12 0x13 0x15 0x16 0x18 0x19 0x1b 0x1c 0x1e 0x1f>;
			clock-output-names = "vcp1", "vcp0", "vpc1", "vpc0", "jpu", "ssp1", "tmu1", "3dg", "2ddmac", "fdp1-2", "fdp1-1", "fdp1-0", "tmu3", "tmu2", "cmt0", "tmu0", "vsp1-du1", "vsp1-du0", "vsp1-rt", "vsp1-sy";
			linux,phandle = <0x7>;
			phandle = <0x7>;
		};

		mstp2_clks@e6150138 {
			compatible = "renesas,r8a7790-mstp-clocks", "renesas,cpg-mstp-clocks";
			reg = <0x0 0xe6150138 0x0 0x4 0x0 0xe6150040 0x0 0x4>;
			clocks = <0x37 0x37 0x37 0x37 0x37 0x37 0x37 0x37 0x37 0x38 0x38>;
			#clock-cells = <0x1>;
			clock-indices = <0x2 0x3 0x4 0x5 0x6 0x7 0x8 0xf 0x10 0x12 0x13>;
			clock-output-names = "scifa2", "scifa1", "scifa0", "msiof2", "scifb0", "scifb1", "msiof1", "msiof3", "scifb2", "sys-dmac1", "sys-dmac0";
			linux,phandle = <0xa>;
			phandle = <0xa>;
		};

		mstp3_clks@e615013c {
			compatible = "renesas,r8a7790-mstp-clocks", "renesas,cpg-mstp-clocks";
			reg = <0x0 0xe615013c 0x0 0x4 0x0 0xe6150048 0x0 0x4>;
			clocks = <0x3e 0x3d 0x3f 0x40 0x41 0x2 0x8 0x2 0x7 0x42 0x3e 0x37 0x3e 0x37 0x3c 0x3e 0x3e>;
			#clock-cells = <0x1>;
			clock-indices = <0x0 0x4 0x5 0xb 0xc 0xd 0xe 0xf 0x12 0x13 0x17 0x1c 0x1d 0x1e 0x1f>;
			clock-output-names = "iic2", "tpu0", "mmcif1", "sdhi3", "sdhi2", "sdhi1", "sdhi0", "mmcif0", "iic0", "pciec", "iic1", "ssusb", "cmt1", "usbdmac0", "usbdmac1";
			linux,phandle = <0x8>;
			phandle = <0x8>;
		};

		mstp4_clks@e6150140 {
			compatible = "renesas,r8a7790-mstp-clocks", "renesas,cpg-mstp-clocks";
			reg = <0x0 0xe6150140 0x0 0x4 0x0 0xe615004c 0x0 0x4>;
			clocks = <0x3d>;
			#clock-cells = <0x1>;
			clock-indices = <0x7>;
			clock-output-names = "irqc";
			linux,phandle = <0x9>;
			phandle = <0x9>;
		};

		mstp5_clks@e6150144 {
			compatible = "renesas,r8a7790-mstp-clocks", "renesas,cpg-mstp-clocks";
			reg = <0x0 0xe6150144 0x0 0x4 0x0 0xe615003c 0x0 0x4>;
			clocks = <0x3e 0x3e 0x2 0xb 0x34 0x3a>;
			#clock-cells = <0x1>;
			clock-indices = <0x2 0x1 0x6 0x16 0x17>;
			clock-output-names = "audmac0", "audmac1", "adsp_mod", "thermal", "pwm";
			linux,phandle = <0x6>;
			phandle = <0x6>;
		};

		mstp7_clks@e615014c {
			compatible = "renesas,r8a7790-mstp-clocks", "renesas,cpg-mstp-clocks";
			reg = <0x0 0xe615014c 0x0 0x4 0x0 0xe61501c4 0x0 0x4>;
			clocks = <0x37 0x3e 0x38 0x38 0x3a 0x3a 0x43 0x43 0x43 0x43 0x43>;
			#clock-cells = <0x1>;
			clock-indices = <0x3 0x4 0x10 0x11 0x14 0x15 0x16 0x17 0x18 0x19 0x1a>;
			clock-output-names = "ehci", "hsusb", "hscif1", "hscif0", "scif1", "scif0", "du2", "du1", "du0", "lvds1", "lvds0";
			linux,phandle = <0x21>;
			phandle = <0x21>;
		};

		mstp8_clks@e6150990 {
			compatible = "renesas,r8a7790-mstp-clocks", "renesas,cpg-mstp-clocks";
			reg = <0x0 0xe6150990 0x0 0x4 0x0 0xe61509a0 0x0 0x4>;
			clocks = <0x3e 0x3b 0x3b 0x3b 0x3b 0x3e 0x3a 0x38 0x38>;
			#clock-cells = <0x1>;
			clock-indices = <0x2 0x8 0x9 0xa 0xb 0xc 0xd 0xe 0xf>;
			clock-output-names = "mlb", "vin3", "vin2", "vin1", "vin0", "etheravb", "ether", "sata1", "sata0";
			linux,phandle = <0x23>;
			phandle = <0x23>;
		};

		mstp9_clks@e6150994 {
			compatible = "renesas,r8a7790-mstp-clocks", "renesas,cpg-mstp-clocks";
			reg = <0x0 0xe6150994 0x0 0x4 0x0 0xe61509a4 0x0 0x4>;
			clocks = <0x3d 0x3d 0x3d 0x3d 0x3d 0x3d 0x3a 0x3a 0x2 0x5 0x3d 0x3e 0x3e 0x3e 0x3e>;
			#clock-cells = <0x1>;
			clock-indices = <0x7 0x8 0x9 0xa 0xb 0xc 0xf 0x10 0x11 0x1a 0x1c 0x1d 0x1e 0x1f>;
			clock-output-names = "gpio5", "gpio4", "gpio3", "gpio2", "gpio1", "gpio0", "rcan1", "rcan0", "qspi_mod", "iic3", "i2c3", "i2c2", "i2c1", "i2c0";
			linux,phandle = <0x5>;
			phandle = <0x5>;
		};

		mstp10_clks@e6150998 {
			compatible = "renesas,r8a7790-mstp-clocks", "renesas,cpg-mstp-clocks";
			reg = <0x0 0xe6150998 0x0 0x4 0x0 0xe61509a8 0x0 0x4>;
			clocks = <0x3a 0x3a 0x3a 0x3a 0x3a 0x3a 0x3a 0x3a 0x3a 0x3a 0x3a 0x3a 0x44 0x11 0x44 0x11 0x44 0x11 0x44 0x11 0x44 0x11 0x44 0x11 0x44 0x11 0x44 0x11 0x44 0x11 0x44 0x11 0x44 0x11 0x44 0x11 0x44 0x11 0x44 0x11>;
			#clock-cells = <0x1>;
			clock-indices = <0x5 0x6 0x7 0x8 0x9 0xa 0xb 0xc 0xd 0xe 0xf 0x11 0x12 0x13 0x14 0x15 0x16 0x17 0x18 0x19 0x1a 0x1b 0x1c 0x1d 0x1e 0x1f>;
			clock-output-names = "ssi-all", "ssi9", "ssi8", "ssi7", "ssi6", "ssi5", "ssi4", "ssi3", "ssi2", "ssi1", "ssi0", "scu-all", "scu-dvc1", "scu-dvc0", "scu-ctu1-mix1", "scu-ctu0-mix0", "scu-src9", "scu-src8", "scu-src7", "scu-src6", "scu-src5", "scu-src4", "scu-src3", "scu-src2", "scu-src1", "scu-src0";
			linux,phandle = <0x44>;
			phandle = <0x44>;
		};
	};

	spi@e6b10000 {
		compatible = "renesas,qspi-r8a7790", "renesas,qspi";
		reg = <0x0 0xe6b10000 0x0 0x2c>;
		interrupts = <0x0 0xb8 0x4>;
		clocks = <0x5 0x11>;
		dmas = <0xb 0x17 0xb 0x18>;
		dma-names = "tx", "rx";
		power-domains = <0x2>;
		num-cs = <0x1>;
		#address-cells = <0x1>;
		#size-cells = <0x0>;
		status = "okay";
		pinctrl-0 = <0x45>;
		pinctrl-names = "default";

		flash@0 {
			compatible = "spansion,s25fl512s", "jedec,spi-nor";
			reg = <0x0>;
			spi-max-frequency = <0x1c9c380>;
			spi-tx-bus-width = <0x4>;
			spi-rx-bus-width = <0x4>;
			spi-cpha;
			spi-cpol;
			m25p,fast-read;

			partitions {
				compatible = "fixed-partitions";
				#address-cells = <0x1>;
				#size-cells = <0x1>;

				partition@0 {
					label = "loader";
					reg = <0x0 0x40000>;
					read-only;
				};

				partition@40000 {
					label = "user";
					reg = <0x40000 0x400000>;
					read-only;
				};

				partition@440000 {
					label = "flash";
					reg = <0x440000 0x3bc0000>;
				};
			};
		};
	};

	spi@e6e20000 {
		compatible = "renesas,msiof-r8a7790";
		reg = <0x0 0xe6e20000 0x0 0x64>;
		interrupts = <0x0 0x9c 0x4>;
		clocks = <0x46 0x0>;
		dmas = <0xb 0x51 0xb 0x52>;
		dma-names = "tx", "rx";
		power-domains = <0x2>;
		#address-cells = <0x1>;
		#size-cells = <0x0>;
		status = "disabled";
	};

	spi@e6e10000 {
		compatible = "renesas,msiof-r8a7790";
		reg = <0x0 0xe6e10000 0x0 0x64>;
		interrupts = <0x0 0x9d 0x4>;
		clocks = <0xa 0x8>;
		dmas = <0xb 0x55 0xb 0x56>;
		dma-names = "tx", "rx";
		power-domains = <0x2>;
		#address-cells = <0x1>;
		#size-cells = <0x0>;
		status = "okay";
		pinctrl-0 = <0x47>;
		pinctrl-names = "default";

		pmic@0 {
			compatible = "renesas,r2a11302ft";
			reg = <0x0>;
			spi-max-frequency = <0x5b8d80>;
			spi-cpol;
			spi-cpha;
		};
	};

	spi@e6e00000 {
		compatible = "renesas,msiof-r8a7790";
		reg = <0x0 0xe6e00000 0x0 0x64>;
		interrupts = <0x0 0x9e 0x4>;
		clocks = <0xa 0x5>;
		dmas = <0xb 0x41 0xb 0x42>;
		dma-names = "tx", "rx";
		power-domains = <0x2>;
		#address-cells = <0x1>;
		#size-cells = <0x0>;
		status = "disabled";
	};

	spi@e6c90000 {
		compatible = "renesas,msiof-r8a7790";
		reg = <0x0 0xe6c90000 0x0 0x64>;
		interrupts = <0x0 0x9f 0x4>;
		clocks = <0xa 0xf>;
		dmas = <0xb 0x45 0xb 0x46>;
		dma-names = "tx", "rx";
		power-domains = <0x2>;
		#address-cells = <0x1>;
		#size-cells = <0x0>;
		status = "disabled";
	};

	usb@ee000000 {
		compatible = "renesas,xhci-r8a7790";
		reg = <0x0 0xee000000 0x0 0xc00>;
		interrupts = <0x0 0x65 0x4>;
		clocks = <0x8 0x1c>;
		power-domains = <0x2>;
		phys = <0x48 0x1>;
		phy-names = "usb";
		status = "okay";
		pinctrl-0 = <0x49>;
		pinctrl-names = "default";
	};

	pci@ee090000 {
		compatible = "renesas,pci-r8a7790";
		device_type = "pci";
		reg = <0x0 0xee090000 0x0 0xc00 0x0 0xee080000 0x0 0x1100>;
		interrupts = <0x0 0x6c 0x4>;
		clocks = <0x21 0x3>;
		power-domains = <0x2>;
		status = "okay";
		bus-range = <0x0 0x0>;
		#address-cells = <0x3>;
		#size-cells = <0x2>;
		#interrupt-cells = <0x1>;
		ranges = <0x2000000 0x0 0xee080000 0x0 0xee080000 0x0 0x10000>;
		interrupt-map-mask = <0xff00 0x0 0x0 0x7>;
		interrupt-map = <0x0 0x0 0x0 0x1 0x1 0x0 0x6c 0x4 0x800 0x0 0x0 0x1 0x1 0x0 0x6c 0x4 0x1000 0x0 0x0 0x2 0x1 0x0 0x6c 0x4>;
		pinctrl-0 = <0x4a>;
		pinctrl-names = "default";

		usb@0,1 {
			reg = <0x800 0x0 0x0 0x0 0x0>;
			device_type = "pci";
			phys = <0x29 0x0>;
			phy-names = "usb";
			#address-cells = <0x3>;
			#size-cells = <0x2>;
			ranges;
		};

		usb@0,2 {
			reg = <0x1000 0x0 0x0 0x0 0x0>;
			device_type = "pci";
			phys = <0x29 0x0>;
			phy-names = "usb";
			#address-cells = <0x3>;
			#size-cells = <0x2>;
			ranges;
		};
	};

	pci@ee0b0000 {
		compatible = "renesas,pci-r8a7790";
		device_type = "pci";
		reg = <0x0 0xee0b0000 0x0 0xc00 0x0 0xee0a0000 0x0 0x1100>;
		interrupts = <0x0 0x70 0x4>;
		clocks = <0x21 0x3>;
		power-domains = <0x2>;
		status = "okay";
		bus-range = <0x1 0x1>;
		#address-cells = <0x3>;
		#size-cells = <0x2>;
		#interrupt-cells = <0x1>;
		ranges = <0x2000000 0x0 0xee0a0000 0x0 0xee0a0000 0x0 0x10000>;
		interrupt-map-mask = <0xff00 0x0 0x0 0x7>;
		interrupt-map = <0x0 0x0 0x0 0x1 0x1 0x0 0x70 0x4 0x800 0x0 0x0 0x1 0x1 0x0 0x70 0x4 0x1000 0x0 0x0 0x2 0x1 0x0 0x70 0x4>;
		pinctrl-0 = <0x4b>;
		pinctrl-names = "default";
	};

	pci@ee0d0000 {
		compatible = "renesas,pci-r8a7790";
		device_type = "pci";
		clocks = <0x21 0x3>;
		power-domains = <0x2>;
		reg = <0x0 0xee0d0000 0x0 0xc00 0x0 0xee0c0000 0x0 0x1100>;
		interrupts = <0x0 0x71 0x4>;
		status = "okay";
		bus-range = <0x2 0x2>;
		#address-cells = <0x3>;
		#size-cells = <0x2>;
		#interrupt-cells = <0x1>;
		ranges = <0x2000000 0x0 0xee0c0000 0x0 0xee0c0000 0x0 0x10000>;
		interrupt-map-mask = <0xff00 0x0 0x0 0x7>;
		interrupt-map = <0x0 0x0 0x0 0x1 0x1 0x0 0x71 0x4 0x800 0x0 0x0 0x1 0x1 0x0 0x71 0x4 0x1000 0x0 0x0 0x2 0x1 0x0 0x71 0x4>;
		pinctrl-0 = <0x49>;
		pinctrl-names = "default";

		usb@0,1 {
			reg = <0x800 0x0 0x0 0x0 0x0>;
			device_type = "pci";
			phys = <0x48 0x0>;
			phy-names = "usb";
			#address-cells = <0x3>;
			#size-cells = <0x2>;
			ranges;
		};

		usb@0,2 {
			reg = <0x1000 0x0 0x0 0x0 0x0>;
			device_type = "pci";
			phys = <0x48 0x0>;
			phy-names = "usb";
			#address-cells = <0x3>;
			#size-cells = <0x2>;
			ranges;
		};
	};

	pcie@fe000000 {
		compatible = "renesas,pcie-r8a7790";
		reg = <0x0 0xfe000000 0x0 0x80000>;
		#address-cells = <0x3>;
		#size-cells = <0x2>;
		bus-range = <0x0 0xff>;
		device_type = "pci";
		ranges = <0x1000000 0x0 0x0 0x0 0xfe100000 0x0 0x100000 0x2000000 0x0 0xfe200000 0x0 0xfe200000 0x0 0x200000 0x2000000 0x0 0x30000000 0x0 0x30000000 0x0 0x8000000 0x42000000 0x0 0x38000000 0x0 0x38000000 0x0 0x8000000>;
		dma-ranges = <0x42000000 0x0 0x40000000 0x0 0x40000000 0x0 0x80000000 0x43000000 0x1 0x80000000 0x1 0x80000000 0x0 0x80000000>;
		interrupts = <0x0 0x74 0x4 0x0 0x75 0x4 0x0 0x76 0x4>;
		#interrupt-cells = <0x1>;
		interrupt-map-mask = <0x0 0x0 0x0 0x0>;
		interrupt-map = <0x0 0x0 0x0 0x0 0x1 0x0 0x74 0x4>;
		clocks = <0x8 0x13 0x4c>;
		clock-names = "pcie", "pcie_bus";
		power-domains = <0x2>;
		status = "disabled";
	};

	sound@ec500000 {
		compatible = "renesas,rcar_sound-r8a7790", "renesas,rcar_sound-gen2";
		reg = <0x0 0xec500000 0x0 0x1000 0x0 0xec5a0000 0x0 0x100 0x0 0xec540000 0x0 0x1000 0x0 0xec541000 0x0 0x280 0x0 0xec740000 0x0 0x200>;
		reg-names = "scu", "adg", "ssiu", "ssi", "audmapp";
		clocks = <0x44 0x5 0x44 0x6 0x44 0x7 0x44 0x8 0x44 0x9 0x44 0xa 0x44 0xb 0x44 0xc 0x44 0xd 0x44 0xe 0x44 0xf 0x44 0x16 0x44 0x17 0x44 0x18 0x44 0x19 0x44 0x1a 0x44 0x1b 0x44 0x1c 0x44 0x1d 0x44 0x1e 0x44 0x1f 0x44 0x15 0x44 0x14 0x44 0x15 0x44 0x14 0x44 0x13 0x44 0x12 0x4d 0x4e 0x4f 0x39>;
		clock-names = "ssi-all", "ssi.9", "ssi.8", "ssi.7", "ssi.6", "ssi.5", "ssi.4", "ssi.3", "ssi.2", "ssi.1", "ssi.0", "src.9", "src.8", "src.7", "src.6", "src.5", "src.4", "src.3", "src.2", "src.1", "src.0", "ctu.0", "ctu.1", "mix.0", "mix.1", "dvc.0", "dvc.1", "clk_a", "clk_b", "clk_c", "clk_i";
		power-domains = <0x2>;
		status = "okay";
		pinctrl-0 = <0x50 0x51>;
		pinctrl-names = "default";
		#sound-dai-cells = <0x0>;
		linux,phandle = <0x5c>;
		phandle = <0x5c>;

		rcar_sound,dvc {

			dvc@0 {
				dmas = <0x52 0xbc>;
				dma-names = "tx";
				linux,phandle = <0x56>;
				phandle = <0x56>;
			};

			dvc@1 {
				dmas = <0x52 0xbe>;
				dma-names = "tx";
				linux,phandle = <0x59>;
				phandle = <0x59>;
			};
		};

		rcar_sound,mix {

			mix@0 {
			};

			mix@1 {
			};
		};

		rcar_sound,ctu {

			ctu@0 {
			};

			ctu@1 {
			};

			ctu@2 {
			};

			ctu@3 {
			};

			ctu@4 {
			};

			ctu@5 {
			};

			ctu@6 {
			};

			ctu@7 {
			};
		};

		rcar_sound,src {

			src@0 {
				interrupts = <0x0 0x160 0x4>;
				dmas = <0x52 0x85 0x53 0x9a>;
				dma-names = "rx", "tx";
			};

			src@1 {
				interrupts = <0x0 0x161 0x4>;
				dmas = <0x52 0x87 0x53 0x9c>;
				dma-names = "rx", "tx";
			};

			src@2 {
				interrupts = <0x0 0x162 0x4>;
				dmas = <0x52 0x89 0x53 0x9e>;
				dma-names = "rx", "tx";
				linux,phandle = <0x55>;
				phandle = <0x55>;
			};

			src@3 {
				interrupts = <0x0 0x163 0x4>;
				dmas = <0x52 0x8b 0x53 0xa0>;
				dma-names = "rx", "tx";
				linux,phandle = <0x58>;
				phandle = <0x58>;
			};

			src@4 {
				interrupts = <0x0 0x164 0x4>;
				dmas = <0x52 0x8d 0x53 0xb0>;
				dma-names = "rx", "tx";
			};

			src@5 {
				interrupts = <0x0 0x165 0x4>;
				dmas = <0x52 0x8f 0x53 0xb2>;
				dma-names = "rx", "tx";
			};

			src@6 {
				interrupts = <0x0 0x166 0x4>;
				dmas = <0x52 0x91 0x53 0xb4>;
				dma-names = "rx", "tx";
			};

			src@7 {
				interrupts = <0x0 0x167 0x4>;
				dmas = <0x52 0x93 0x53 0xb6>;
				dma-names = "rx", "tx";
			};

			src@8 {
				interrupts = <0x0 0x168 0x4>;
				dmas = <0x52 0x95 0x53 0xb8>;
				dma-names = "rx", "tx";
			};

			src@9 {
				interrupts = <0x0 0x169 0x4>;
				dmas = <0x52 0x97 0x53 0xba>;
				dma-names = "rx", "tx";
			};
		};

		rcar_sound,ssi {

			ssi@0 {
				interrupts = <0x0 0x172 0x4>;
				dmas = <0x52 0x1 0x53 0x2 0x52 0x15 0x53 0x16>;
				dma-names = "rx", "tx", "rxu", "txu";
				linux,phandle = <0x54>;
				phandle = <0x54>;
			};

			ssi@1 {
				interrupts = <0x0 0x173 0x4>;
				dmas = <0x52 0x3 0x53 0x4 0x52 0x49 0x53 0x4a>;
				dma-names = "rx", "tx", "rxu", "txu";
				shared-pin;
				linux,phandle = <0x57>;
				phandle = <0x57>;
			};

			ssi@2 {
				interrupts = <0x0 0x174 0x4>;
				dmas = <0x52 0x5 0x53 0x6 0x52 0x63 0x53 0x64>;
				dma-names = "rx", "tx", "rxu", "txu";
			};

			ssi@3 {
				interrupts = <0x0 0x175 0x4>;
				dmas = <0x52 0x7 0x53 0x8 0x52 0x6f 0x53 0x70>;
				dma-names = "rx", "tx", "rxu", "txu";
			};

			ssi@4 {
				interrupts = <0x0 0x176 0x4>;
				dmas = <0x52 0x9 0x53 0xa 0x52 0x71 0x53 0x72>;
				dma-names = "rx", "tx", "rxu", "txu";
			};

			ssi@5 {
				interrupts = <0x0 0x177 0x4>;
				dmas = <0x52 0xb 0x53 0xc 0x52 0x73 0x53 0x74>;
				dma-names = "rx", "tx", "rxu", "txu";
			};

			ssi@6 {
				interrupts = <0x0 0x178 0x4>;
				dmas = <0x52 0xd 0x53 0xe 0x52 0x75 0x53 0x76>;
				dma-names = "rx", "tx", "rxu", "txu";
			};

			ssi@7 {
				interrupts = <0x0 0x179 0x4>;
				dmas = <0x52 0xf 0x53 0x10 0x52 0x79 0x53 0x7a>;
				dma-names = "rx", "tx", "rxu", "txu";
			};

			ssi@8 {
				interrupts = <0x0 0x17a 0x4>;
				dmas = <0x52 0x11 0x53 0x12 0x52 0x7b 0x53 0x7c>;
				dma-names = "rx", "tx", "rxu", "txu";
			};

			ssi@9 {
				interrupts = <0x0 0x17b 0x4>;
				dmas = <0x52 0x13 0x53 0x14 0x52 0x7d 0x53 0x7e>;
				dma-names = "rx", "tx", "rxu", "txu";
			};
		};

		rcar_sound,dai {

			dai0 {
				playback = <0x54 0x55 0x56>;
				capture = <0x57 0x58 0x59>;
			};
		};
	};

	mmu@e6280000 {
		compatible = "renesas,ipmmu-r8a7790", "renesas,ipmmu-vmsa";
		reg = <0x0 0xe6280000 0x0 0x1000>;
		interrupts = <0x0 0xdf 0x4 0x0 0xe0 0x4>;
		#iommu-cells = <0x1>;
		status = "disabled";
	};

	mmu@e6290000 {
		compatible = "renesas,ipmmu-r8a7790", "renesas,ipmmu-vmsa";
		reg = <0x0 0xe6290000 0x0 0x1000>;
		interrupts = <0x0 0xe1 0x4>;
		#iommu-cells = <0x1>;
		status = "disabled";
	};

	mmu@e6740000 {
		compatible = "renesas,ipmmu-r8a7790", "renesas,ipmmu-vmsa";
		reg = <0x0 0xe6740000 0x0 0x1000>;
		interrupts = <0x0 0xc6 0x4 0x0 0xc7 0x4>;
		#iommu-cells = <0x1>;
		status = "disabled";
	};

	mmu@ec680000 {
		compatible = "renesas,ipmmu-r8a7790", "renesas,ipmmu-vmsa";
		reg = <0x0 0xec680000 0x0 0x1000>;
		interrupts = <0x0 0xe2 0x4>;
		#iommu-cells = <0x1>;
		status = "disabled";
	};

	mmu@fe951000 {
		compatible = "renesas,ipmmu-r8a7790", "renesas,ipmmu-vmsa";
		reg = <0x0 0xfe951000 0x0 0x1000>;
		interrupts = <0x0 0xde 0x4 0x0 0xdd 0x4>;
		#iommu-cells = <0x1>;
		status = "disabled";
	};

	mmu@ffc80000 {
		compatible = "renesas,ipmmu-r8a7790", "renesas,ipmmu-vmsa";
		reg = <0x0 0xffc80000 0x0 0x1000>;
		interrupts = <0x0 0x133 0x4>;
		#iommu-cells = <0x1>;
		status = "disabled";
	};

	chosen {
		stdout-path = "/serial@e6e60000";
		bootargs = "earlyprink console=ttySC6,38400 debug ignore_loglevel rw rootfstype=ext3 root=/dev/mmcblk1p1 rootwait vmalloc=384M";
	};

	memory@40000000 {
		device_type = "memory";
		reg = <0x0 0x40000000 0x0 0x10000000>;
	};

	lbsc {
		#address-cells = <0x1>;
		#size-cells = <0x1>;
	};

	keyboard {
		compatible = "gpio-keys";

		button@1 {
			linux,code = <0x2>;
			label = "SW2-1";
			wakeup-source;
			debounce-interval = <0x14>;
			gpios = <0x11 0xe 0x1>;
		};

		button@2 {
			linux,code = <0x3>;
			label = "SW2-2";
			wakeup-source;
			debounce-interval = <0x14>;
			gpios = <0x11 0x18 0x1>;
		};

		button@3 {
			linux,code = <0x4>;
			label = "SW2-3";
			wakeup-source;
			debounce-interval = <0x14>;
			gpios = <0x11 0x1a 0x1>;
		};

		button@4 {
			linux,code = <0x5>;
			label = "SW2-4";
			wakeup-source;
			debounce-interval = <0x14>;
			gpios = <0x11 0x1c 0x1>;
		};
	};

	leds {
		compatible = "gpio-leds";

		led6 {
			gpios = <0x5a 0x16 0x0>;
		};

		led7 {
			gpios = <0x5a 0x17 0x0>;
		};

		led8 {
			gpios = <0x2b 0x11 0x0>;
		};
	};

	fixedregulator@0 {
		compatible = "regulator-fixed";
		regulator-name = "fixed-3.3V";
		regulator-min-microvolt = <0x325aa0>;
		regulator-max-microvolt = <0x325aa0>;
		regulator-boot-on;
		regulator-always-on;
		linux,phandle = <0x17>;
		phandle = <0x17>;
	};

	regulator@1 {
		compatible = "regulator-fixed";
		regulator-name = "SDHI0 Vcc";
		regulator-min-microvolt = <0x325aa0>;
		regulator-max-microvolt = <0x325aa0>;
		gpio = <0x2b 0x18 0x0>;
		enable-active-high;
		linux,phandle = <0x1a>;
		phandle = <0x1a>;
	};

	regulator@2 {
		compatible = "regulator-gpio";
		regulator-name = "SDHI0 VccQ";
		regulator-min-microvolt = <0x1b7740>;
		regulator-max-microvolt = <0x325aa0>;
		gpios = <0x2b 0x1d 0x0>;
		gpios-states = <0x1>;
		states = <0x325aa0 0x1 0x1b7740 0x0>;
		linux,phandle = <0x1b>;
		phandle = <0x1b>;
	};

	regulator@3 {
		compatible = "regulator-fixed";
		regulator-name = "SDHI2 Vcc";
		regulator-min-microvolt = <0x325aa0>;
		regulator-max-microvolt = <0x325aa0>;
		gpio = <0x2b 0x19 0x0>;
		enable-active-high;
		linux,phandle = <0x1e>;
		phandle = <0x1e>;
	};

	regulator@4 {
		compatible = "regulator-gpio";
		regulator-name = "SDHI2 VccQ";
		regulator-min-microvolt = <0x1b7740>;
		regulator-max-microvolt = <0x325aa0>;
		gpios = <0x2b 0x1e 0x0>;
		gpios-states = <0x1>;
		states = <0x325aa0 0x1 0x1b7740 0x0>;
		linux,phandle = <0x1f>;
		phandle = <0x1f>;
	};

	clock {
		compatible = "fixed-clock";
		#clock-cells = <0x0>;
		clock-frequency = <0xac4400>;
		clock-output-names = "audio_clock";
		linux,phandle = <0x5e>;
		phandle = <0x5e>;
	};

	sound {
		compatible = "simple-audio-card";
		simple-audio-card,format = "left_j";
		simple-audio-card,bitclock-master = <0x5b>;
		simple-audio-card,frame-master = <0x5b>;

		simple-audio-card,cpu {
			sound-dai = <0x5c>;
		};

		simple-audio-card,codec {
			sound-dai = <0x5d>;
			clocks = <0x5e>;
			linux,phandle = <0x5b>;
			phandle = <0x5b>;
		};
	};

	vga-encoder {
		compatible = "adi,adv7123";

		ports {
			#address-cells = <0x1>;
			#size-cells = <0x0>;

			port@0 {
				reg = <0x0>;

				endpoint {
					remote-endpoint = <0x5f>;
					linux,phandle = <0x31>;
					phandle = <0x31>;
				};
			};

			port@1 {
				reg = <0x1>;

				endpoint {
					remote-endpoint = <0x60>;
					linux,phandle = <0x61>;
					phandle = <0x61>;
				};
			};
		};
	};

	vga {
		compatible = "vga-connector";

		port {

			endpoint {
				remote-endpoint = <0x61>;
				linux,phandle = <0x60>;
				phandle = <0x60>;
			};
		};
	};

	hdmi-out {
		compatible = "hdmi-connector";
		type = [61 00];

		port {

			endpoint {
				remote-endpoint = <0x62>;
				linux,phandle = <0x13>;
				phandle = <0x13>;
			};
		};
	};

	x2-clock {
		compatible = "fixed-clock";
		#clock-cells = <0x0>;
		clock-frequency = <0x8d9ee20>;
		linux,phandle = <0x2f>;
		phandle = <0x2f>;
	};

	x13-clock {
		compatible = "fixed-clock";
		#clock-cells = <0x0>;
		clock-frequency = <0x8d9ee20>;
		linux,phandle = <0x2e>;
		phandle = <0x2e>;
	};

	reset@e6160000 {
		reg = <0x0 0xe6160000 0x0 0x20000>;
	};

	arm-generic-counter@e6080000 {
		reg = <0x0 0xe6080000 0x0 0x20000>;
	};

	inter-connect-ram1@e63c0000 {
		reg = <0x0 0xe63c0000 0x0 0x50000>;
	};

	sysc@e6180000 {
		reg = <0x0 0xe6180000 0x0 0x40000>;
	};
};
